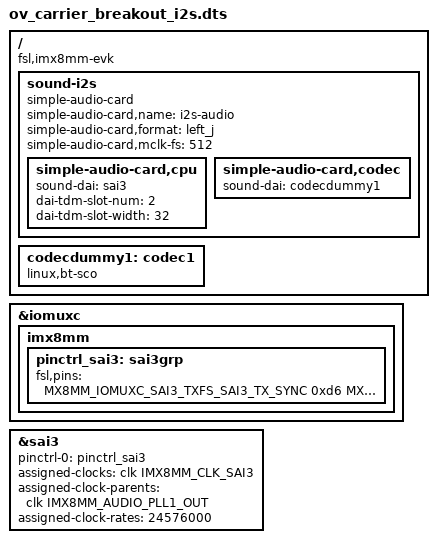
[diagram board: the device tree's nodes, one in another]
/**
 * Portenta-M8 dtb overlay file
 * Arduino 2021
 * Enable I2S on Arduino Breakout carrier board
 * A generic sound card is also created together
 * with a dummy codec using bt-sco. In this way the alsa interface
 * streams i2s signals without the need to have
 * a real codec device connected.
 * The i2s signals are configured with left_j format.
 */

/dts-v1/;
/plugin/;

#include "imx8mm-pinfunc.h"
#include <dt-bindings/clock/imx8mm-clock.h>

/ {
	compatible = "fsl,imx8mm-evk", "fsl,imx8mm";

	fragment@0 {
		target = <&iomuxc>;
		__overlay__ {
			imx8mm {
				pinctrl_sai3: sai3grp {
					fsl,pins = <
						MX8MM_IOMUXC_SAI3_TXFS_SAI3_TX_SYNC			0xd6
						MX8MM_IOMUXC_SAI3_TXC_SAI3_TX_BCLK			0xd6
						MX8MM_IOMUXC_SAI3_TXD_SAI3_TX_DATA0			0xd6
						MX8MM_IOMUXC_SAI3_RXD_SAI3_RX_DATA0			0xd6
					>;
				};
			};
		};
	};

	fragment@1 {
		target = <&sai3>;
		__overlay__ {
			pinctrl-names = "default";
			pinctrl-0 = <&pinctrl_sai3>;
			assigned-clocks = <&clk IMX8MM_CLK_SAI3>;
			assigned-clock-parents = <&clk IMX8MM_AUDIO_PLL1_OUT>;
			assigned-clock-rates = <24576000>;
			#sound-dai-cells = <0>;
			status = "okay";
		};
	};

	fragment@2 {
		target-path = "/";
		__overlay__ {
			sound-i2s {
				compatible = "simple-audio-card";
				simple-audio-card,name = "i2s-audio";
				simple-audio-card,format = "left_j";
				simple-audio-card,mclk-fs = <512>;

				simple-audio-card,cpu {
					sound-dai = <&sai3>;
					dai-tdm-slot-num = <2>;
					dai-tdm-slot-width = <32>;
				};

				simple-audio-card,codec {
					sound-dai = <&codecdummy1>;
				};
			};
		};
	};

	fragment@3 {
		target-path = "/";
		__overlay__ {
			codecdummy1: codec1 {
				#sound-dai-cells = <0>;
				compatible = "linux,bt-sco";
				status = "okay";
			};
		};
	};
};
